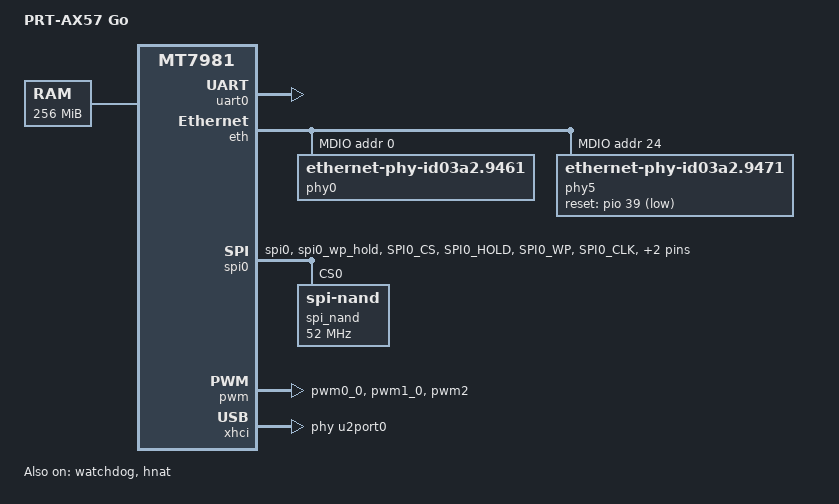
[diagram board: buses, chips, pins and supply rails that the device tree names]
/dts-v1/;
#include "mt7981.dtsi"
/ {
	model = "PRT-AX57 Go";
	compatible = "mediatek,mt7981-spim-snand-rfb";
	sw_btn = "0";

	chosen {
		bootargs = "console=ttyS0,115200n1 loglevel=8  \
				earlycon=uart8250,mmio32,0x11002000";
	};

	memory {
		// fpga ddr2: 128MB*2
		reg = <0 0x40000000 0 0x10000000>;
	};

	reserved-memory {
		/* 24 KiB reserved for PWM[ch0,ch1,ch2] */
		pwm_reserved: pwmbuf@4C7FA000 {
			reg = <0 0x4C7FA000 0 0x6000>;
			no-map;
		};
	};

	aliases {
		ethernet0 = "/ethernet@15100000/mac@0";
		ethernet1 = "/ethernet@15100000/mac@1";
	};

	timer {
		clock-frequency = <12996791>;
	};
};

&uart0 {
	status = "okay";
};

&watchdog {
	status = "okay";
};

&eth {
        status = "okay";

        gmac0: mac@0 {
		compatible = "mediatek,eth-mac";
		reg = <0>;
		phy-mode = "sgmii";
		phy-handle = <&phy5>;
		local-mac-address = [000000000000];
	};

	gmac1: mac@1 {
                compatible = "mediatek,eth-mac";
                reg = <1>;
		phy-mode = "gmii";
		phy-handle = <&phy0>;
		local-mac-address = [000000000000];
        };

        mdio: mdio-bus {
                #address-cells = <1>;
                #size-cells = <0>;

                phy0: ethernet-phy@0 {
			compatible = "ethernet-phy-id03a2.9461";
			reg = <0>;
			phy-mode = "gmii";
			nvmem-cells = <&phy_calibration>;
			nvmem-cell-names = "phy-cal-data";
                };
		phy5: phy@5 {
			compatible = "ethernet-phy-id03a2.9471";
			reg = <24>;
			reset-gpios = <&pio 39 1>;
			reset-assert-us = <600>;
			reset-deassert-us = <20000>;
			phy-mode = "sgmii";
			full-duplex;
			pause;
		};
        };
};

&hnat {
	mtketh-wan = "eth1";
	mtketh-lan = "eth0";
	mtketh-max-gmac = <2>;
	status = "okay";
};

&spi0 {
	pinctrl-names = "default";
	pinctrl-0 = <&spi0_flash_pins>;
	status = "okay";
	spi_nand: spi_nand@0 {
		#address-cells = <1>;
		#size-cells = <1>;
		compatible = "spi-nand";
		reg = <0>;
		spi-max-frequency = <52000000>;
		spi-tx-buswidth = <4>;
		spi-rx-buswidth = <4>;
	};
};

&spi1 {
	pinctrl-names = "default";
	pinctrl-0 = <&spic_pins>;
	status = "disabled";
};

&pio {

	i2c_pins: i2c-pins-g0 {
                mux {
                        function = "i2c";
                        groups = "i2c0_0";
                };
        };

        pcm_pins: pcm-pins-g0 {
                mux {
                        function = "pcm";
                        groups = "pcm";
                };
        };

        pwm0_pin: pwm0-pin-g0 {
                mux {
                        function = "pwm";
                        groups = "pwm0_0";  // GPIO 13
                };
        };

        pwm1_pin: pwm1-pin-g1 {
                mux {
                        function = "pwm";
                        groups = "pwm1_0";  // GPIO 14
                };
        };

        pwm2_pin: pwm2-pin {
                mux {
                        function = "pwm";
                        groups = "pwm2";   // GPIO 7
                };
        };

	spi0_flash_pins: spi0-pins {
		mux {
			function = "spi";
			groups = "spi0", "spi0_wp_hold";
		};

		conf-pu {
			pins = "SPI0_CS", "SPI0_HOLD", "SPI0_WP";
			drive-strength = <MTK_DRIVE_8mA>;
			bias-pull-up = <MTK_PUPD_SET_R1R0_11>;
		};

		conf-pd {
			pins = "SPI0_CLK", "SPI0_MOSI", "SPI0_MISO";
			drive-strength = <MTK_DRIVE_8mA>;
			bias-pull-down = <MTK_PUPD_SET_R1R0_11>;
		};
	};

	spic_pins: spi1-pins {
		mux {
			function = "spi";
			groups = "spi1_1";
		};
	};

	uart1_pins: uart1-pins-g1 {
                mux {
                        function = "uart";
                        groups = "uart1_1";
                };
        };

	uart2_pins: uart2-pins-g1 {
		mux {
                        function = "uart";
                        groups = "uart2_1";
                };
        };
};

&pwm {
	pinctrl-names = "default";
	pinctrl-0 = <&pwm0_pin &pwm1_pin &pwm2_pin>;
	interrupts = <GIC_SPI 137 IRQ_TYPE_LEVEL_HIGH>;
	status = "okay";
};

&xhci {
	mediatek,u3p-dis-msk = <0x0>;
	phys = <&u2port0 PHY_TYPE_USB2>,
	       <&u3port0 PHY_TYPE_USB3>;
	status = "okay";
};
